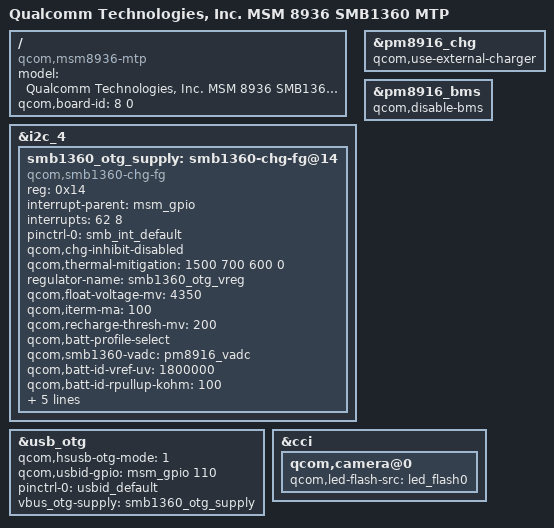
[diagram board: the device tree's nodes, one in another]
/* Copyright (c) 2014, The Linux Foundation. All rights reserved.
*
* This program is free software; you can redistribute it and/or modify
* it under the terms of the GNU General Public License version 2 and
* only version 2 as published by the Free Software Foundation.
*
* This program is distributed in the hope that it will be useful,
* but WITHOUT ANY WARRANTY; without even the implied warranty of
* MERCHANTABILITY or FITNESS FOR A PARTICULAR PURPOSE.  See the
* GNU General Public License for more details.
*/

/dts-v1/;

#include "msm8936.dtsi"
#include "msm8939-mtp.dtsi"
#include "msm8939-audio-internal_codec.dtsi"

/ {
	model = "Qualcomm Technologies, Inc. MSM 8936 SMB1360 MTP";
	compatible = "qcom,msm8936-mtp", "qcom,msm8936", "qcom,mtp";
	qcom,board-id = <8 0>;
};

&i2c_4 {
	smb1360_otg_supply: smb1360-chg-fg@14 {
		compatible = "qcom,smb1360-chg-fg";
		reg = <0x14>;
		interrupt-parent = <&msm_gpio>;
		interrupts = <62 8>;
		pinctrl-names = "default";
		pinctrl-0 = <&smb_int_default>;
		//qcom,charging-disabled; //CORE-DL-ImplementChgAlg-00
		qcom,chg-inhibit-disabled;
		qcom,thermal-mitigation = <1500 700 600 0>;
		regulator-name = "smb1360_otg_vreg";
		//CORE-DL-ImplementChgAlg-00 +[
		qcom,float-voltage-mv = <4350>;
		qcom,iterm-ma = <100>;
		qcom,recharge-thresh-mv = <200>;
		qcom,batt-profile-select;
		qcom,smb1360-vadc = <&pm8916_vadc>;
		qcom,batt-id-vref-uv = <1800000>;
		qcom,batt-id-rpullup-kohm = <100>;
		qcom,profile-a-rid-kohm = <324>;
		qcom,profile-b-rid-kohm = <181>;
		qcom,shdn-after-pwroff;
		//qcom,fg-reset-at-pon;
		//qcom,fg-reset-thresold-mv = <25>;
		qcom,empty-soc-disabled; //CORE-DL-DisableEmptySoc-00
		qcom,fg-auto-recharge-soc = <99>;
		//CORE-DL-ImplementChgAlg-00 +]
	};
};

&pm8916_chg {
	status = "ok";
	qcom,use-external-charger;
};

&pm8916_bms {
	status = "ok";
	qcom,disable-bms;
};

&usb_otg {
	qcom,hsusb-otg-mode = <1>;
	qcom,usbid-gpio = <&msm_gpio 110 0>;
	pinctrl-names = "default";
	pinctrl-0 = <&usbid_default>;
	vbus_otg-supply = <&smb1360_otg_supply>;
};

&cci {
	qcom,camera@0 {
		qcom,led-flash-src = <&led_flash0>;
	};
};
